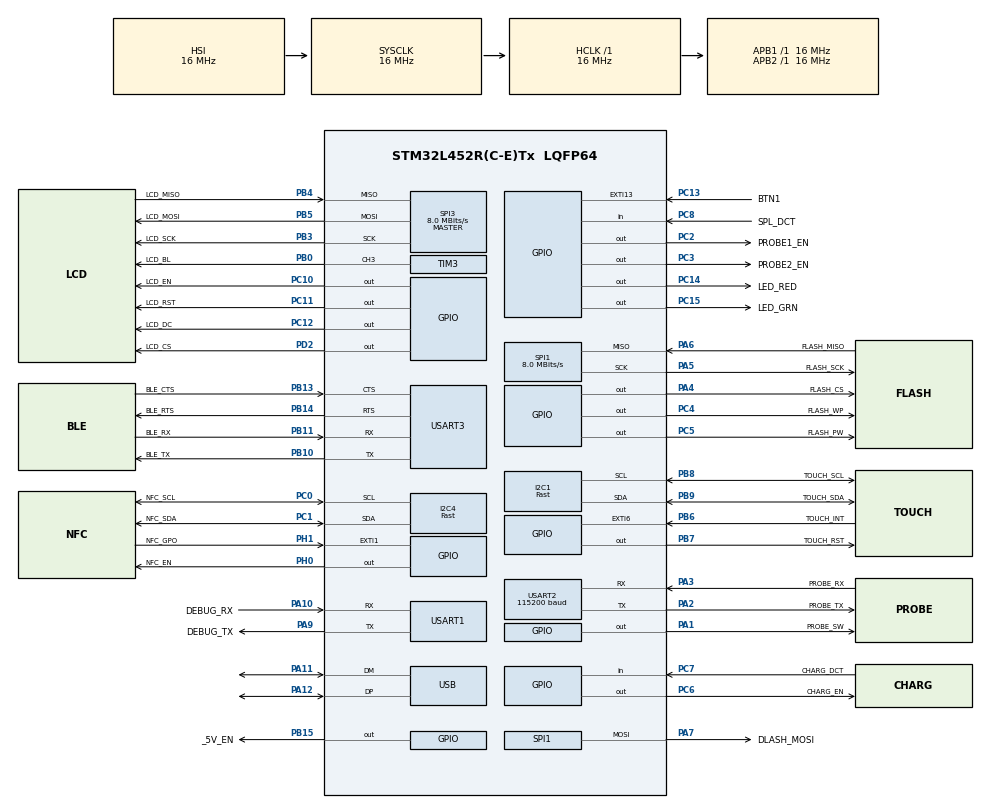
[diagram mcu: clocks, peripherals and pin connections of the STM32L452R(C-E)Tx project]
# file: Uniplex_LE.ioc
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I2C1.I2C_Speed_Mode=I2C_Fast
I2C1.Timing=0x0010061A
I2C4.I2C_Speed_Mode=I2C_Fast
I2C4.Timing=0x0010061A
Mcu.Family=STM32L4
Mcu.Name=STM32L452R(C-E)Tx
Mcu.Package=LQFP64
NVIC.EXTI15_10_IRQn=true\:0\:0\:false\:false\:true\:true\:true\:true
NVIC.EXTI1_IRQn=true\:0\:0\:false\:false\:true\:true\:true\:true
NVIC.EXTI9_5_IRQn=true\:0\:0\:false\:false\:true\:true\:true\:true
NVIC.PriorityGroup=NVIC_PRIORITYGROUP_4
NVIC.SPI3_IRQn=true\:0\:0\:false\:false\:true\:true\:true\:true
NVIC.USART2_IRQn=true\:0\:0\:false\:false\:true\:true\:true\:true
NVIC.USART3_IRQn=true\:0\:0\:false\:false\:true\:true\:true\:true
NVIC.USB_IRQn=true\:0\:0\:false\:false\:true\:true\:true\:true
PA0.GPIO_Label=RTC_INT
PA0.Mode=SYS_WakeUp0
PA0.Signal=SYS_WKUP1
PA1.GPIO_Label=PROBE_SW
PA1.Signal=GPIO_Output
PA10.GPIO_Label=DEBUG_RX
PA10.Mode=Asynchronous
PA10.Signal=USART1_RX
PA11.Mode=Device
PA11.Signal=USB_DM
PA12.Mode=Device
PA12.Signal=USB_DP
PA13\ (JTMS/SWDIO).Mode=Serial_Wire
PA13\ (JTMS/SWDIO).Signal=SYS_JTMS-SWDIO
PA14\ (JTCK/SWCLK).Mode=Serial_Wire
PA14\ (JTCK/SWCLK).Signal=SYS_JTCK-SWCLK
PA2.GPIO_Label=PROBE_TX
PA2.Mode=Asynchronous
PA2.Signal=USART2_TX
PA3.GPIO_Label=PROBE_RX
PA3.Mode=Asynchronous
PA3.Signal=USART2_RX
PA4.GPIO_Label=FLASH_CS
PA4.Signal=GPIO_Output
PA5.GPIO_Label=FLASH_SCK
PA5.Mode=Full_Duplex_Master
PA5.Signal=SPI1_SCK
PA6.GPIO_Label=FLASH_MISO
PA6.Mode=Full_Duplex_Master
PA6.Signal=SPI1_MISO
PA7.GPIO_Label=DLASH_MOSI
PA7.Mode=Full_Duplex_Master
PA7.Signal=SPI1_MOSI
PA9.GPIO_Label=DEBUG_TX
PA9.Mode=Asynchronous
PA9.Signal=USART1_TX
PB0.GPIO_Label=LCD_BL
PB0.Signal=S_TIM3_CH3
PB10.GPIO_Label=BLE_TX
PB10.Mode=Asynchronous
PB10.Signal=USART3_TX
PB11.GPIO_Label=BLE_RX
PB11.Mode=Asynchronous
PB11.Signal=USART3_RX
PB13.GPIO_Label=BLE_CTS
PB13.Mode=CTS_RTS
PB13.Signal=USART3_CTS
PB14.GPIO_Label=BLE_RTS
PB14.Mode=CTS_RTS
PB14.Signal=USART3_RTS
PB15.GPIO_Label=_5V_EN
PB15.Signal=GPIO_Output
PB3\ (JTDO/TRACESWO).GPIO_Label=LCD_SCK
PB3\ (JTDO/TRACESWO).Mode=Full_Duplex_Master
PB3\ (JTDO/TRACESWO).Signal=SPI3_SCK
PB4\ (NJTRST).GPIO_Label=LCD_MISO
PB4\ (NJTRST).Mode=Full_Duplex_Master
PB4\ (NJTRST).Signal=SPI3_MISO
PB5.GPIO_Label=LCD_MOSI
PB5.Mode=Full_Duplex_Master
PB5.Signal=SPI3_MOSI
PB6.GPIO_Label=TOUCH_INT
PB6.Signal=GPXTI6
PB7.GPIO_Label=TOUCH_RST
PB7.Signal=GPIO_Output
PB8.GPIO_Label=TOUCH_SCL
PB8.Mode=I2C
PB8.Signal=I2C1_SCL
PB9.GPIO_Label=TOUCH_SDA
PB9.Mode=I2C
PB9.Signal=I2C1_SDA
PC0.GPIO_Label=NFC_SCL
PC0.Mode=I2C
PC0.Signal=I2C4_SCL
PC1.GPIO_Label=NFC_SDA
PC1.Mode=I2C
PC1.Signal=I2C4_SDA
PC10.GPIO_Label=LCD_EN
PC10.Signal=GPIO_Output
PC11.GPIO_Label=LCD_RST
PC11.Signal=GPIO_Output
PC12.GPIO_Label=LCD_DC
PC12.Signal=GPIO_Output
PC13.GPIO_Label=BTN1
PC13.Signal=GPXTI13
PC14-OSC32_IN\ (PC14).GPIO_Label=LED_RED
PC14-OSC32_IN\ (PC14).Signal=GPIO_Output
PC15-OSC32_OUT\ (PC15).GPIO_Label=LED_GRN
PC15-OSC32_OUT\ (PC15).Signal=GPIO_Output
PC2.GPIO_Label=PROBE1_EN
PC2.Signal=GPIO_Output
PC3.GPIO_Label=PROBE2_EN
PC3.Signal=GPIO_Output
PC4.GPIO_Label=FLASH_WP
PC4.Signal=GPIO_Output
PC5.GPIO_Label=FLASH_PW
PC5.Signal=GPIO_Output
PC6.GPIO_Label=CHARG_EN
PC6.Signal=GPIO_Output
PC7.GPIO_Label=CHARG_DCT
PC7.Signal=GPIO_Input
PC8.GPIO_Label=SPL_DCT
PC8.Signal=GPIO_Input
PD2.GPIO_Label=LCD_CS
PD2.Signal=GPIO_Output
PH0-OSC_IN\ (PH0).GPIO_Label=NFC_EN
PH0-OSC_IN\ (PH0).Signal=GPIO_Output
PH1-OSC_OUT\ (PH1).GPIO_Label=NFC_GPO
PH1-OSC_OUT\ (PH1).Signal=GPXTI1
ProjectManager.HeapSize=0x200
ProjectManager.StackSize=0x400
ProjectManager.TargetToolchain=STM32CubeIDE
RCC.ADCFreq_Value=192000000
RCC.AHBFreq_Value=16000000
RCC.APB1Freq_Value=16000000
RCC.APB1TimFreq_Value=16000000
RCC.APB2Freq_Value=16000000
RCC.APB2TimFreq_Value=16000000
RCC.CK48CLockSelection=RCC_USBCLKSOURCE_HSI48
RCC.CortexFreq_Value=16000000
RCC.HCLKFreq_Value=16000000
RCC.HSE_VALUE=8000000
RCC.HSI48_VALUE=48000000
RCC.HSI_VALUE=16000000
RCC.I2C1CLockSelection=RCC_I2C1CLKSOURCE_HSI
RCC.I2C4CLockSelection=RCC_I2C4CLKSOURCE_HSI
RCC.LSE_VALUE=32768
RCC.MSIClockRange=RCC_MSIRANGE_8
RCC.MSI_VALUE=16000000
RCC.PLLN=40
RCC.PLLSAI1N=24
RCC.PREFETCH_ENABLE=0
RCC.SYSCLKFreq_VALUE=16000000
RCC.SYSCLKSource=RCC_SYSCLKSOURCE_HSI
RCC.USART1CLockSelection=RCC_USART1CLKSOURCE_HSI
RCC.USART2CLockSelection=RCC_USART2CLKSOURCE_HSI
RCC.USART3CLockSelection=RCC_USART3CLKSOURCE_HSI
RCC.USBFreq_Value=48000000
RCC.VCOOutputFreq_Value=640000000
SH.S_TIM3_CH3.0=TIM3_CH3,PWM Generation3 CH3
SPI1.CalculateBaudRate=8.0 MBits/s
SPI1.DataSize=SPI_DATASIZE_8BIT
SPI1.Direction=SPI_DIRECTION_2LINES
SPI1.Mode=SPI_MODE_MASTER
SPI1.VirtualType=VM_MASTER
SPI3.CalculateBaudRate=8.0 MBits/s
SPI3.DataSize=SPI_DATASIZE_8BIT
SPI3.Direction=SPI_DIRECTION_2LINES
SPI3.Mode=SPI_MODE_MASTER
SPI3.VirtualType=VM_MASTER
TIM3.Channel-PWM\ Generation3\ CH3=TIM_CHANNEL_3
USART1.VirtualMode-Asynchronous=VM_ASYNC
USART2.BaudRate=115200
USART2.VirtualMode-Asynchronous=VM_ASYNC
USART3.VirtualMode-Asynchronous=VM_ASYNC
USB_DEVICE.CLASS_NAME_FS=CDC
USB_DEVICE.VirtualMode=Cdc
USB_DEVICE.VirtualModeFS=Cdc_FS
VP_CRC_VS_CRC.Mode=CRC_Activate
VP_TIM3_VS_ClockSourceINT.Mode=Internal
VP_USB_DEVICE_VS_USB_DEVICE_CDC_FS.Mode=CDC_FS
board=custom

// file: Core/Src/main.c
/* USER CODE BEGIN Header */
/**
  ******************************************************************************
  * @file           : main.c
  * @brief          : Main program body
  ******************************************************************************
  * @attention
  *
  * Copyright (c) 2023 STMicroelectronics.
  * All rights reserved.
  *
  * This software is licensed under terms that can be found in the LICENSE file
  * in the root directory of this software component.
  * If no LICENSE file comes with this software, it is provided AS-IS.
  *
  ******************************************************************************
  */
/* USER CODE END Header */
#include "main.h"
#include "crc.h"
#include "i2c.h"
#include "spi.h"
#include "tim.h"
#include "usart.h"
#include "usb_device.h"
#include "gpio.h"

void SystemClock_Config(void);

int main(void)
{
  /* USER CODE BEGIN 1 */

	// Local variables
	HAL_StatusTypeDef state;
  /* USER CODE END 1 */

  /* MCU Configuration--------------------------------------------------------*/

  /* Reset of all peripherals, Initializes the Flash interface and the Systick. */
  HAL_Init();

  /* Configure the system clock */
  SystemClock_Config();

  /* Initialize all configured peripherals */
  MX_GPIO_Init();
  MX_CRC_Init();
  MX_I2C1_Init();
  MX_I2C4_Init();
  MX_SPI1_Init();
  MX_SPI3_Init();
  MX_TIM3_Init();
  MX_USART1_UART_Init();
  MX_USART2_UART_Init();
  MX_USART3_UART_Init();
  MX_USB_DEVICE_Init();
  /* USER CODE BEGIN 2 */

  // Init system modules .......................................................
  state = init_sys( );

  // Check system state
  if( HAL_OK != state )
  {
	  // An error occured in initilaization, system can not start!
	  Error_Handler( );
  }

  // END of initialization .....................................................

  /* USER CODE END 2 */

  /* Infinite loop */
  /* USER CODE BEGIN WHILE */
  while (1)
  {

	  // Check open Tasks???

	  // Do Tasks
	  // Go to Sleep
	  handler_line( );

    /* USER CODE END WHILE */

  }
}

void SystemClock_Config(void)
{
  RCC_OscInitTypeDef RCC_OscInitStruct = {0};
  RCC_ClkInitTypeDef RCC_ClkInitStruct = {0};

  /** Configure the main internal regulator output voltage
  */
  if (HAL_PWREx_ControlVoltageScaling(PWR_REGULATOR_VOLTAGE_SCALE1) != HAL_OK)
  {
    Error_Handler();
  }

  /** Initializes the RCC Oscillators according to the specified parameters
  * in the RCC_OscInitTypeDef structure.
  */
  RCC_OscInitStruct.OscillatorType = RCC_OSCILLATORTYPE_HSI48|RCC_OSCILLATORTYPE_HSI;
  RCC_OscInitStruct.HSIState = RCC_HSI_ON;
  RCC_OscInitStruct.HSI48State = RCC_HSI48_ON;
  RCC_OscInitStruct.HSICalibrationValue = RCC_HSICALIBRATION_DEFAULT;
  RCC_OscInitStruct.PLL.PLLState = RCC_PLL_NONE;
  if (HAL_RCC_OscConfig(&RCC_OscInitStruct) != HAL_OK)
  {
    Error_Handler();
  }

  /** Initializes the CPU, AHB and APB buses clocks
  */
  RCC_ClkInitStruct.ClockType = RCC_CLOCKTYPE_HCLK|RCC_CLOCKTYPE_SYSCLK
                              |RCC_CLOCKTYPE_PCLK1|RCC_CLOCKTYPE_PCLK2;
  RCC_ClkInitStruct.SYSCLKSource = RCC_SYSCLKSOURCE_HSI;
  RCC_ClkInitStruct.AHBCLKDivider = RCC_SYSCLK_DIV1;
  RCC_ClkInitStruct.APB1CLKDivider = RCC_HCLK_DIV1;
  RCC_ClkInitStruct.APB2CLKDivider = RCC_HCLK_DIV1;

  if (HAL_RCC_ClockConfig(&RCC_ClkInitStruct, FLASH_LATENCY_0) != HAL_OK)
  {
    Error_Handler();
  }
}

/* USER CODE BEGIN 4 */

/**
  * @brief  EXTI line detection callback.
  * @param  GPIO_Pin Specifies the port pin connected to corresponding EXTI line.
  * @retval None
  */
void HAL_GPIO_EXTI_Callback( uint16_t GPIO_Pin )
{
	// Local variables

	// Define struct pointer
	st_task *pst_task = &gst_task;

	if( GPIO_Pin == NFC_GPO_Pin )
	{
		pst_task->task_id = TASK_NFC;
		handler_add_task( );
	}
}

/* USER CODE END 4 */

void Error_Handler(void)
{
  __disable_irq();
  while (1)
  {
  }
}
